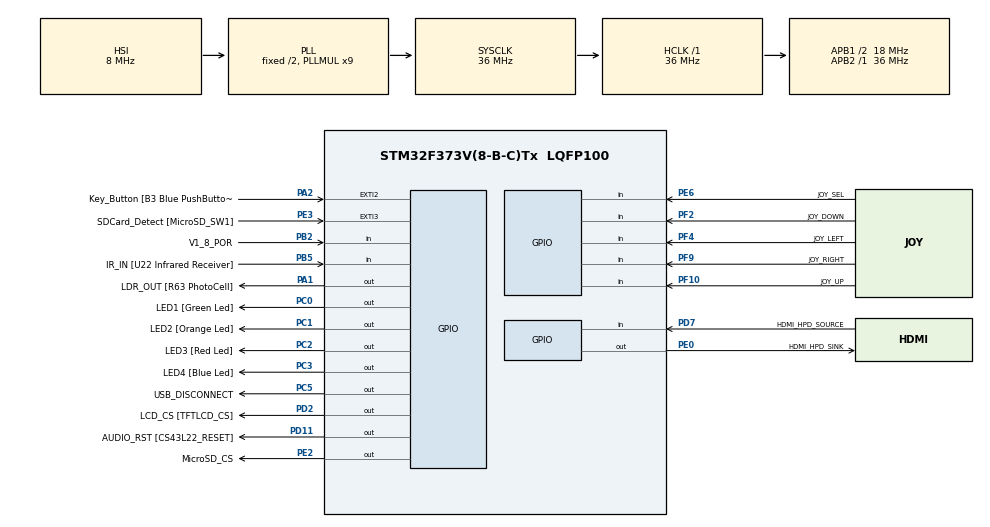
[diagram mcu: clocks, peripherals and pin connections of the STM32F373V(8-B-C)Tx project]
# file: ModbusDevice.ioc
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Mcu.Family=STM32F3
Mcu.Name=STM32F373V(8-B-C)Tx
Mcu.Package=LQFP100
NVIC.PriorityGroup=NVIC_PRIORITYGROUP_0
PA0.GPIO_Label=WAKEUP [B2 PushButton]
PA0.Signal=SYS_WKUP1
PA1.GPIO_Label=LDR_OUT [R63 PhotoCell]
PA1.GPIO_ModeDefaultOutputPP=GPIO_MODE_OUTPUT_PP
PA1.GPIO_PuPd=GPIO_NOPULL
PA1.GPIO_Speed=GPIO_SPEED_FREQ_LOW
PA1.Signal=GPIO_Output
PA10.GPIO_Label=I2C2_SDA [STLM75M2E_SDA]
PA10.GPIO_Mode=GPIO_MODE_AF_OD
PA10.GPIO_PuPd=GPIO_NOPULL
PA10.GPIO_Speed=GPIO_SPEED_FREQ_LOW
PA10.Signal=I2C2_SDA
PA11.Signal=USB_DM
PA12.Signal=USB_DP
PA13.GPIO_Label=TMS/SWDIO
PA13.Signal=SYS_JTMS-SWDIO
PA14.GPIO_Label=TMS/SWCLK
PA14.Signal=SYS_JTCK-SWCLK
PA15.GPIO_Label=TDI
PA15.Signal=SYS_JTDI
PA2.GPIO_Label=Key_Button [B3 Blue PushButton]
PA2.GPIO_ModeDefaultEXTI=GPIO_MODE_EVT_RISING
PA2.GPIO_PuPd=GPIO_NOPULL
PA2.Signal=GPXTI2
PA3.GPIO_Label=COM_IN+
PA3.GPIO_Mode=GPIO_MODE_ANALOG
PA3.GPIO_PuPd=GPIO_NOPULL
PA3.Signal=COMP2_INP
PA4.GPIO_Label=ADC_DAC_SAR1 [CN11]
PA4.GPIO_Mode=GPIO_MODE_ANALOG
PA4.GPIO_PuPd=GPIO_NOPULL
PA4.Signal=ADC1_IN4
PA5.GPIO_Label=ADC_DAC_SAR2 [CN10]
PA5.GPIO_Mode=GPIO_MODE_ANALOG
PA5.GPIO_PuPd=GPIO_NOPULL
PA5.Signal=ADC1_IN5
PA6.GPIO_Label=ECG_DAC [ElectroCardiogram]
PA6.GPIO_Mode=GPIO_MODE_ANALOG
PA6.GPIO_PuPd=GPIO_NOPULL
PA6.Signal=COMP_DAC21_group
PA7.GPIO_Label=COMP_OUT [LD9 Green Led]
PA7.GPIO_Mode=GPIO_MODE_AF_PP
PA7.GPIO_PuPd=GPIO_NOPULL
PA7.GPIO_Speed=GPIO_SPEED_FREQ_LOW
PA7.Signal=COMP2_OUT
PA8.GPIO_Label=I2C2_SMB [STLM75M2E_INT]
PA8.GPIO_Mode=GPIO_MODE_AF_OD
PA8.GPIO_PuPd=GPIO_NOPULL
PA8.GPIO_Speed=GPIO_SPEED_FREQ_LOW
PA8.Signal=I2C2_SMBA
PA9.GPIO_Label=I2C2_SCL [STLM75M2E_SCL]
PA9.GPIO_Mode=GPIO_MODE_AF_OD
PA9.GPIO_PuPd=GPIO_NOPULL
PA9.GPIO_Speed=GPIO_SPEED_FREQ_LOW
PA9.Signal=I2C2_SCL
PB0.GPIO_Label=MIC_IN [Microphone]
PB0.GPIO_Mode=GPIO_MODE_ANALOG
PB0.GPIO_PuPd=GPIO_NOPULL
PB0.Signal=ADC1_IN8
PB1.GPIO_Label=ADC_POT_IN [RV3 Potentiometer]
PB1.GPIO_Mode=GPIO_MODE_ANALOG
PB1.GPIO_PuPd=GPIO_NOPULL
PB1.Signal=ADC1_IN9
PB2.GPIO_Label=V1_8_POR
PB2.GPIO_Mode=GPIO_MODE_INPUT
PB2.GPIO_PuPd=GPIO_NOPULL
PB2.Signal=GPIO_Input
PB3.GPIO_Label=TDO/SWO
PB3.Signal=SYS_JTDO-TRACESWO
PB4.GPIO_Label=TRST
PB4.Signal=SYS_NJTRST
PB5.GPIO_Label=IR_IN [U22 Infrared Receiver]
PB5.GPIO_Mode=GPIO_MODE_INPUT
PB5.GPIO_PuPd=GPIO_NOPULL
PB5.Signal=GPIO_Input
PB6.GPIO_Label=I2C1_SCL [HDMI_SCL]
PB6.GPIO_Mode=GPIO_MODE_AF_OD
PB6.GPIO_PuPd=GPIO_NOPULL
PB6.GPIO_Speed=GPIO_SPEED_FREQ_LOW
PB6.Signal=I2C1_SCL
PB7.GPIO_Label=I2C1_SDA [HDMI_SDA]
PB7.GPIO_Mode=GPIO_MODE_AF_OD
PB7.GPIO_PuPd=GPIO_NOPULL
PB7.GPIO_Speed=GPIO_SPEED_FREQ_LOW
PB7.Signal=I2C1_SDA
PB8.GPIO_Label=HDMI_CEC
PB8.GPIO_Mode=GPIO_MODE_AF_PP
PB8.GPIO_PuPd=GPIO_NOPULL
PB8.GPIO_Speed=GPIO_SPEED_FREQ_LOW
PB8.Signal=CEC
PB9.GPIO_FM9=__NULL
PB9.GPIO_Label=IR_LED [LD10 Infrared Led]
PB9.GPIO_ModeDefaultPP=GPIO_MODE_AF_PP
PB9.GPIO_PuPd=GPIO_NOPULL
PB9.GPIO_Speed=GPIO_SPEED_FREQ_LOW
PB9.Signal=IR_OUT
PC0.GPIO_Label=LED1 [Green Led]
PC0.GPIO_ModeDefaultOutputPP=GPIO_MODE_OUTPUT_OD
PC0.GPIO_PuPd=GPIO_NOPULL
PC0.GPIO_Speed=GPIO_SPEED_FREQ_LOW
PC0.Signal=GPIO_Output
PC1.GPIO_Label=LED2 [Orange Led]
PC1.GPIO_ModeDefaultOutputPP=GPIO_MODE_OUTPUT_OD
PC1.GPIO_PuPd=GPIO_NOPULL
PC1.GPIO_Speed=GPIO_SPEED_FREQ_LOW
PC1.Signal=GPIO_Output
PC10.GPIO_Label=SPI3_SCK [TFTLCD_SCL]
PC10.GPIO_Mode=GPIO_MODE_AF_PP
PC10.GPIO_PuPd=GPIO_NOPULL
PC10.GPIO_Speed=GPIO_SPEED_FREQ_LOW
PC10.Signal=SPI3_SCK
PC11.GPIO_Label=SPI3_MISO [TFTLCD_SDO]
PC11.GPIO_Mode=GPIO_MODE_AF_PP
PC11.GPIO_PuPd=GPIO_NOPULL
PC11.GPIO_Speed=GPIO_SPEED_FREQ_LOW
PC11.Signal=SPI3_MISO
PC12.GPIO_Label=SPI3_MOSI [TFTLCD_SDI]
PC12.GPIO_Mode=GPIO_MODE_AF_PP
PC12.GPIO_PuPd=GPIO_NOPULL
PC12.GPIO_Speed=GPIO_SPEED_FREQ_LOW
PC12.Signal=SPI3_MOSI
PC14-OSC32_IN.GPIO_Label=PC14-OSC32_IN
PC14-OSC32_IN.Signal=RCC_OSC32_IN
PC15-OSC32_OUT.GPIO_Label=PC15-OSC32_OUT
PC15-OSC32_OUT.Signal=RCC_OSC32_OUT
PC2.GPIO_Label=LED3 [Red Led]
PC2.GPIO_ModeDefaultOutputPP=GPIO_MODE_OUTPUT_OD
PC2.GPIO_PuPd=GPIO_NOPULL
PC2.GPIO_Speed=GPIO_SPEED_FREQ_LOW
PC2.Signal=GPIO_Output
PC3.GPIO_Label=LED4 [Blue Led]
PC3.GPIO_ModeDefaultOutputPP=GPIO_MODE_OUTPUT_OD
PC3.GPIO_PuPd=GPIO_NOPULL
PC3.GPIO_Speed=GPIO_SPEED_FREQ_LOW
PC3.Signal=GPIO_Output
PC5.GPIO_Label=USB_DISCONNECT
PC5.GPIO_ModeDefaultOutputPP=GPIO_MODE_OUTPUT_PP
PC5.GPIO_PuPd=GPIO_NOPULL
PC5.GPIO_Speed=GPIO_SPEED_FREQ_LOW
PC5.Signal=GPIO_Output
PC6.GPIO_Label=I2S_CMD [CS43L22_LRCK]
PC6.GPIO_Mode=GPIO_MODE_AF_PP
PC6.GPIO_PuPd=GPIO_NOPULL
PC6.GPIO_Speed=GPIO_SPEED_FREQ_LOW
PC6.Signal=I2S1_WS
PC7.GPIO_Label=I2S_CK [CS43L22_SCLK]
PC7.GPIO_Mode=GPIO_MODE_AF_PP
PC7.GPIO_PuPd=GPIO_NOPULL
PC7.GPIO_Speed=GPIO_SPEED_FREQ_LOW
PC7.Signal=I2S1_CK
PC8.GPIO_Label=I2S_MCLK [CS43L22_MCLK]
PC8.GPIO_Mode=GPIO_MODE_AF_PP
PC8.GPIO_PuPd=GPIO_NOPULL
PC8.GPIO_Speed=GPIO_SPEED_FREQ_LOW
PC8.Signal=I2S1_MCK
PC9.GPIO_Label=I2S_DIN [CS43L22_SDIN]
PC9.GPIO_Mode=GPIO_MODE_AF_PP
PC9.GPIO_PuPd=GPIO_NOPULL
PC9.GPIO_Speed=GPIO_SPEED_FREQ_LOW
PC9.Signal=I2S1_SD
PD0.GPIO_Label=CAN_RX [SN65HVD230D_R]
PD0.GPIO_Mode=GPIO_MODE_AF_PP
PD0.GPIO_PuPd=GPIO_NOPULL
PD0.GPIO_Speed=GPIO_SPEED_FREQ_LOW
PD0.Signal=CAN_RX
PD1.GPIO_Label=CAN_TX [SN65HVD230D_D]
PD1.GPIO_Mode=GPIO_MODE_AF_PP
PD1.GPIO_PuPd=GPIO_NOPULL
PD1.GPIO_Speed=GPIO_SPEED_FREQ_LOW
PD1.Signal=CAN_TX
PD11.GPIO_Label=AUDIO_RST [CS43L22_RESET]
PD11.GPIO_ModeDefaultOutputPP=GPIO_MODE_OUTPUT_PP
PD11.GPIO_PuPd=GPIO_NOPULL
PD11.GPIO_Speed=GPIO_SPEED_FREQ_LOW
PD11.Signal=GPIO_Output
PD12.GPIO_Label=SLIDER_1 [Touch_Slider]
PD12.GPIO_ModeDefaultPP=GPIO_MODE_AF_PP
PD12.GPIO_PuPd=GPIO_NOPULL
PD12.GPIO_Speed=GPIO_SPEED_FREQ_LOW
PD12.Signal=TSC_G8_IO1
PD13.GPIO_Label=SLIDER_2 [Touch_Slider]
PD13.GPIO_ModeDefaultPP=GPIO_MODE_AF_PP
PD13.GPIO_PuPd=GPIO_NOPULL
PD13.GPIO_Speed=GPIO_SPEED_FREQ_LOW
PD13.Signal=TSC_G8_IO2
PD14.GPIO_Label=SLIDER_3 [Touch_Slider]
PD14.GPIO_ModeDefaultPP=GPIO_MODE_AF_PP
PD14.GPIO_PuPd=GPIO_NOPULL
PD14.GPIO_Speed=GPIO_SPEED_FREQ_LOW
PD14.Signal=TSC_G8_IO3
PD15.GPIO_Label=SLIDER_CT [Touch_Slider]
PD15.GPIO_ModeDefaultPP=GPIO_MODE_AF_PP
PD15.GPIO_PuPd=GPIO_NOPULL
PD15.GPIO_Speed=GPIO_SPEED_FREQ_LOW
PD15.Signal=TSC_G8_IO4
PD2.GPIO_Label=LCD_CS [TFTLCD_CS]
PD2.GPIO_ModeDefaultOutputPP=GPIO_MODE_OUTPUT_OD
PD2.GPIO_PuPd=GPIO_NOPULL
PD2.GPIO_Speed=GPIO_SPEED_FREQ_LOW
PD2.Signal=GPIO_Output
PD3.GPIO_Label=USART2_CTS [ST3241_R4OUT]
PD3.GPIO_Mode=GPIO_MODE_AF_PP
PD3.GPIO_PuPd=GPIO_NOPULL
PD3.GPIO_Speed=GPIO_SPEED_FREQ_LOW
PD3.Signal=USART2_CTS
PD4.GPIO_Label=USART2_RTS [ST3241_T1IN]
PD4.GPIO_Mode=GPIO_MODE_AF_PP
PD4.GPIO_PuPd=GPIO_NOPULL
PD4.GPIO_Speed=GPIO_SPEED_FREQ_LOW
PD4.Signal=USART2_RTS
PD5.GPIO_Label=USART2_TX [ST3241_T2IN]
PD5.GPIO_Mode=GPIO_MODE_AF_PP
PD5.GPIO_PuPd=GPIO_NOPULL
PD5.GPIO_Speed=GPIO_SPEED_FREQ_LOW
PD5.Signal=USART2_TX
PD6.GPIO_Label=USART2_RX [ST3241_R3OUT]
PD6.GPIO_Mode=GPIO_MODE_AF_PP
PD6.GPIO_PuPd=GPIO_NOPULL
PD6.GPIO_Speed=GPIO_SPEED_FREQ_LOW
PD6.Signal=USART2_RX
PD7.GPIO_Label=HDMI_HPD_SOURCE
PD7.GPIO_Mode=GPIO_MODE_INPUT
PD7.GPIO_PuPd=GPIO_NOPULL
PD7.Signal=GPIO_Input
PE0.GPIO_Label=HDMI_HPD_SINK
PE0.GPIO_ModeDefaultOutputPP=GPIO_MODE_OUTPUT_OD
PE0.GPIO_PuPd=GPIO_NOPULL
PE0.GPIO_Speed=GPIO_SPEED_FREQ_LOW
PE0.Signal=GPIO_Output
PE11.GPIO_Label=ADC_SD [CN9]
PE11.GPIO_Mode=GPIO_MODE_ANALOG
PE11.GPIO_PuPd=GPIO_NOPULL
PE11.Signal=SDADC1_AIN1P
PE12.GPIO_Label=ECG [ElectroCardiogram]
PE12.GPIO_Mode=GPIO_MODE_ANALOG
PE12.GPIO_PuPd=GPIO_NOPULL
PE12.Signal=SDADC1_AIN0P
PE14.GPIO_Label=PRESSURE_TEMP [MPX2102_GND]
PE14.GPIO_Mode=GPIO_MODE_ANALOG
PE14.GPIO_PuPd=GPIO_NOPULL
PE14.Signal=SDADC2_AIN1P
PE2.GPIO_Label=MicroSD_CS
PE2.GPIO_ModeDefaultOutputPP=GPIO_MODE_OUTPUT_OD
PE2.GPIO_PuPd=GPIO_NOPULL
PE2.GPIO_Speed=GPIO_SPEED_FREQ_LOW
PE2.Signal=GPIO_Output
PE3.GPIO_Label=SDCard_Detect [MicroSD_SW1]
PE3.GPIO_ModeDefaultEXTI=GPIO_MODE_EVT_RISING
PE3.GPIO_PuPd=GPIO_PULLUP
PE3.Signal=GPXTI3
PE4.GPIO_Label=SHIELD [Touch_Slider]
PE4.GPIO_ModeDefaultPP=GPIO_MODE_AF_PP
PE4.GPIO_PuPd=GPIO_NOPULL
PE4.GPIO_Speed=GPIO_SPEED_FREQ_LOW
PE4.Signal=TSC_G7_IO3
PE5.GPIO_Label=SHIELD_CT [Touch_Slider]
PE5.GPIO_ModeDefaultPP=GPIO_MODE_AF_PP
PE5.GPIO_PuPd=GPIO_NOPULL
PE5.GPIO_Speed=GPIO_SPEED_FREQ_LOW
PE5.Signal=TSC_G7_IO4
PE6.GPIO_Label=JOY_SEL
PE6.GPIO_Mode=GPIO_MODE_INPUT
PE6.GPIO_PuPd=GPIO_PULLDOWN
PE6.Signal=GPIO_Input
PE7.GPIO_Label=RTD_IN [Temperature_Sensor]
PE7.GPIO_Mode=GPIO_MODE_ANALOG
PE7.GPIO_PuPd=GPIO_NOPULL
PE7.Signal=SDADC1_AIN3P
PE8.GPIO_Label=PRESSURE_P [MPX2102_Vout+]
PE8.GPIO_Mode=GPIO_MODE_ANALOG
PE8.GPIO_PuPd=GPIO_NOPULL
PE8.Signal=SDADC1_AIN8P
PE9.GPIO_Label=PRESSURE_N [MPX2102_Vout-]
PE9.GPIO_Mode=GPIO_MODE_ANALOG
PE9.GPIO_PuPd=GPIO_NOPULL
PE9.Signal=SDADC1_AIN8M
PF0-OSC_IN.GPIO_Label=PF0-OSC_IN
PF0-OSC_IN.Signal=RCC_OSC_IN
PF1-OSC_OUT.GPIO_Label=PF1-OSC_OUT
PF1-OSC_OUT.Signal=RCC_OSC_OUT
PF10.GPIO_Label=JOY_UP
PF10.GPIO_Mode=GPIO_MODE_INPUT
PF10.GPIO_PuPd=GPIO_PULLDOWN
PF10.Signal=GPIO_Input
PF2.GPIO_Label=JOY_DOWN
PF2.GPIO_Mode=GPIO_MODE_INPUT
PF2.GPIO_PuPd=GPIO_PULLDOWN
PF2.Signal=GPIO_Input
PF4.GPIO_Label=JOY_LEFT
PF4.GPIO_Mode=GPIO_MODE_INPUT
PF4.GPIO_PuPd=GPIO_PULLDOWN
PF4.Signal=GPIO_Input
PF9.GPIO_Label=JOY_RIGHT
PF9.GPIO_Mode=GPIO_MODE_INPUT
PF9.GPIO_PuPd=GPIO_PULLDOWN
PF9.Signal=GPIO_Input
ProjectManager.HeapSize=0x200
ProjectManager.StackSize=0x400
ProjectManager.TargetToolchain=STM32CubeIDE
RCC.AHBFreq_Value=36000000
RCC.APB1CLKDivider=RCC_HCLK_DIV2
RCC.APB1Freq_Value=18000000
RCC.APB1TimFreq_Value=36000000
RCC.APB2Freq_Value=36000000
RCC.APB2TimFreq_Value=36000000
RCC.CortexFreq_Value=36000000
RCC.HCLKFreq_Value=36000000
RCC.HSE_VALUE=8000000
RCC.HSI_VALUE=8000000
RCC.LSE_VALUE=32768
RCC.PLLMUL=RCC_PLL_MUL9
RCC.PRESCALERUSB=RCC_USBCLKSOURCE_PLL_DIV1_5
RCC.SDADCPresc=RCC_SDADCSYSCLK_DIV12
RCC.SYSCLKFreq_VALUE=36000000
RCC.SYSCLKSource=RCC_SYSCLKSOURCE_PLLCLK
RCC.USBFreq_Value=24000000
SH.COMP_DAC21_group.0=DAC2_OUT1
board=STM32373C-EVAL

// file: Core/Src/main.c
/* USER CODE BEGIN Header */
/**
  ******************************************************************************
  * @file           : main.c
  * @brief          : Main program body
  ******************************************************************************
  * @attention
  *
  * Copyright (c) 2023 STMicroelectronics.
  * All rights reserved.
  *
  * This software is licensed under terms that can be found in the LICENSE file
  * in the root directory of this software component.
  * If no LICENSE file comes with this software, it is provided AS-IS.
  *
  ******************************************************************************
  */
/* USER CODE END Header */
#include "main.h"

/* USER CODE BEGIN Includes */
#include "ModbusDevice.h"
/* USER CODE END Includes */

void SystemClock_Config(void);
static void MX_GPIO_Init(void);

int main(void)
{

  /* MCU Configuration--------------------------------------------------------*/

  /* Reset of all peripherals, Initializes the Flash interface and the Systick. */
  HAL_Init();

  /* Configure the system clock */
  SystemClock_Config();

  /* Initialize all configured peripherals */
  MX_GPIO_Init();
  /* USER CODE BEGIN 2 */
  ModbusDevice_Main();
  /* USER CODE END 2 */

  /* Infinite loop */
  while (1)
  {

  }
}

void SystemClock_Config(void)
{
  RCC_OscInitTypeDef RCC_OscInitStruct = {0};
  RCC_ClkInitTypeDef RCC_ClkInitStruct = {0};

  /** Initializes the RCC Oscillators according to the specified parameters
  * in the RCC_OscInitTypeDef structure.
  */
  RCC_OscInitStruct.OscillatorType = RCC_OSCILLATORTYPE_HSI;
  RCC_OscInitStruct.HSIState = RCC_HSI_ON;
  RCC_OscInitStruct.HSICalibrationValue = RCC_HSICALIBRATION_DEFAULT;
  RCC_OscInitStruct.PLL.PLLState = RCC_PLL_ON;
  RCC_OscInitStruct.PLL.PLLSource = RCC_PLLSOURCE_HSI;
  RCC_OscInitStruct.PLL.PLLMUL = RCC_PLL_MUL9;
  if (HAL_RCC_OscConfig(&RCC_OscInitStruct) != HAL_OK)
  {
    Error_Handler();
  }

  /** Initializes the CPU, AHB and APB buses clocks
  */
  RCC_ClkInitStruct.ClockType = RCC_CLOCKTYPE_HCLK|RCC_CLOCKTYPE_SYSCLK
                              |RCC_CLOCKTYPE_PCLK1|RCC_CLOCKTYPE_PCLK2;
  RCC_ClkInitStruct.SYSCLKSource = RCC_SYSCLKSOURCE_PLLCLK;
  RCC_ClkInitStruct.AHBCLKDivider = RCC_SYSCLK_DIV1;
  RCC_ClkInitStruct.APB1CLKDivider = RCC_HCLK_DIV2;
  RCC_ClkInitStruct.APB2CLKDivider = RCC_HCLK_DIV1;

  if (HAL_RCC_ClockConfig(&RCC_ClkInitStruct, FLASH_LATENCY_1) != HAL_OK)
  {
    Error_Handler();
  }
}

static void MX_GPIO_Init(void)
{
  GPIO_InitTypeDef GPIO_InitStruct = {0};

  /* GPIO Ports Clock Enable */
  __HAL_RCC_GPIOE_CLK_ENABLE();
  __HAL_RCC_GPIOC_CLK_ENABLE();
  __HAL_RCC_GPIOF_CLK_ENABLE();
  __HAL_RCC_GPIOA_CLK_ENABLE();
  __HAL_RCC_GPIOB_CLK_ENABLE();
  __HAL_RCC_GPIOD_CLK_ENABLE();

  /*Configure GPIO pin Output Level */
  HAL_GPIO_WritePin(GPIOE, MicroSD_CS_Pin|HDMI_HPD_SINK_Pin, GPIO_PIN_RESET);

  /*Configure GPIO pin Output Level */
  HAL_GPIO_WritePin(GPIOC, LED1_Pin|LED2_Pin|LED3_Pin|LED4_Pin
                          |USB_DISCONNECT_Pin, GPIO_PIN_RESET);

  /*Configure GPIO pin Output Level */
  HAL_GPIO_WritePin(LDR_OUT_GPIO_Port, LDR_OUT_Pin, GPIO_PIN_RESET);

  /*Configure GPIO pin Output Level */
  HAL_GPIO_WritePin(GPIOD, AUDIO_RST_Pin|LCD_CS_Pin, GPIO_PIN_RESET);

  /*Configure GPIO pins : MicroSD_CS_Pin HDMI_HPD_SINK_Pin */
  GPIO_InitStruct.Pin = MicroSD_CS_Pin|HDMI_HPD_SINK_Pin;
  GPIO_InitStruct.Mode = GPIO_MODE_OUTPUT_OD;
  GPIO_InitStruct.Pull = GPIO_NOPULL;
  GPIO_InitStruct.Speed = GPIO_SPEED_FREQ_LOW;
  HAL_GPIO_Init(GPIOE, &GPIO_InitStruct);

  /*Configure GPIO pin : SDCard_Detect_Pin */
  GPIO_InitStruct.Pin = SDCard_Detect_Pin;
  GPIO_InitStruct.Mode = GPIO_MODE_EVT_RISING;
  GPIO_InitStruct.Pull = GPIO_PULLUP;
  HAL_GPIO_Init(SDCard_Detect_GPIO_Port, &GPIO_InitStruct);

  /*Configure GPIO pins : SHIELD_Pin SHIELD_CT_Pin */
  GPIO_InitStruct.Pin = SHIELD_Pin|SHIELD_CT_Pin;
  GPIO_InitStruct.Mode = GPIO_MODE_AF_PP;
  GPIO_InitStruct.Pull = GPIO_NOPULL;
  GPIO_InitStruct.Speed = GPIO_SPEED_FREQ_LOW;
  GPIO_InitStruct.Alternate = GPIO_AF3_TSC;
  HAL_GPIO_Init(GPIOE, &GPIO_InitStruct);

  /*Configure GPIO pin : JOY_SEL_Pin */
  GPIO_InitStruct.Pin = JOY_SEL_Pin;
  GPIO_InitStruct.Mode = GPIO_MODE_INPUT;
  GPIO_InitStruct.Pull = GPIO_PULLDOWN;
  HAL_GPIO_Init(JOY_SEL_GPIO_Port, &GPIO_InitStruct);

  /*Configure GPIO pins : JOY_RIGHT_Pin JOY_UP_Pin JOY_DOWN_Pin JOY_LEFT_Pin */
  GPIO_InitStruct.Pin = JOY_RIGHT_Pin|JOY_UP_Pin|JOY_DOWN_Pin|JOY_LEFT_Pin;
  GPIO_InitStruct.Mode = GPIO_MODE_INPUT;
  GPIO_InitStruct.Pull = GPIO_PULLDOWN;
  HAL_GPIO_Init(GPIOF, &GPIO_InitStruct);

  /*Configure GPIO pins : LED1_Pin LED2_Pin LED3_Pin LED4_Pin */
  GPIO_InitStruct.Pin = LED1_Pin|LED2_Pin|LED3_Pin|LED4_Pin;
  GPIO_InitStruct.Mode = GPIO_MODE_OUTPUT_OD;
  GPIO_InitStruct.Pull = GPIO_NOPULL;
  GPIO_InitStruct.Speed = GPIO_SPEED_FREQ_LOW;
  HAL_GPIO_Init(GPIOC, &GPIO_InitStruct);

  /*Configure GPIO pin : LDR_OUT_Pin */
  GPIO_InitStruct.Pin = LDR_OUT_Pin;
  GPIO_InitStruct.Mode = GPIO_MODE_OUTPUT_PP;
  GPIO_InitStruct.Pull = GPIO_NOPULL;
  GPIO_InitStruct.Speed = GPIO_SPEED_FREQ_LOW;
  HAL_GPIO_Init(LDR_OUT_GPIO_Port, &GPIO_InitStruct);

  /*Configure GPIO pin : Key_Button_Pin */
  GPIO_InitStruct.Pin = Key_Button_Pin;
  GPIO_InitStruct.Mode = GPIO_MODE_EVT_RISING;
  GPIO_InitStruct.Pull = GPIO_NOPULL;
  HAL_GPIO_Init(Key_Button_GPIO_Port, &GPIO_InitStruct);

  /*Configure GPIO pins : COM_IN__Pin ADC_DAC_SAR1_Pin ADC_DAC_SAR2_Pin ECG_DAC_Pin */
  GPIO_InitStruct.Pin = COM_IN__Pin|ADC_DAC_SAR1_Pin|ADC_DAC_SAR2_Pin|ECG_DAC_Pin;
  GPIO_InitStruct.Mode = GPIO_MODE_ANALOG;
  GPIO_InitStruct.Pull = GPIO_NOPULL;
  HAL_GPIO_Init(GPIOA, &GPIO_InitStruct);

  /*Configure GPIO pin : COMP_OUT_Pin */
  GPIO_InitStruct.Pin = COMP_OUT_Pin;
  GPIO_InitStruct.Mode = GPIO_MODE_AF_PP;
  GPIO_InitStruct.Pull = GPIO_NOPULL;
  GPIO_InitStruct.Speed = GPIO_SPEED_FREQ_LOW;
  GPIO_InitStruct.Alternate = GPIO_AF8_COMP2;
  HAL_GPIO_Init(COMP_OUT_GPIO_Port, &GPIO_InitStruct);

  /*Configure GPIO pin : USB_DISCONNECT_Pin */
  GPIO_InitStruct.Pin = USB_DISCONNECT_Pin;
  GPIO_InitStruct.Mode = GPIO_MODE_OUTPUT_PP;
  GPIO_InitStruct.Pull = GPIO_NOPULL;
  GPIO_InitStruct.Speed = GPIO_SPEED_FREQ_LOW;
  HAL_GPIO_Init(USB_DISCONNECT_GPIO_Port, &GPIO_InitStruct);

  /*Configure GPIO pins : MIC_IN_Pin ADC_POT_IN_Pin */
  GPIO_InitStruct.Pin = MIC_IN_Pin|ADC_POT_IN_Pin;
  GPIO_InitStruct.Mode = GPIO_MODE_ANALOG;
  GPIO_InitStruct.Pull = GPIO_NOPULL;
  HAL_GPIO_Init(GPIOB, &GPIO_InitStruct);

  /*Configure GPIO pins : V1_8_POR_Pin IR_IN_Pin */
  GPIO_InitStruct.Pin = V1_8_POR_Pin|IR_IN_Pin;
  GPIO_InitStruct.Mode = GPIO_MODE_INPUT;
  GPIO_InitStruct.Pull = GPIO_NOPULL;
  HAL_GPIO_Init(GPIOB, &GPIO_InitStruct);

  /*Configure GPIO pins : RTD_IN_Pin PRESSURE_P_Pin PRESSURE_N_Pin ADC_SD_Pin
                           ECG_Pin PRESSURE_TEMP_Pin */
  GPIO_InitStruct.Pin = RTD_IN_Pin|PRESSURE_P_Pin|PRESSURE_N_Pin|ADC_SD_Pin
                          |ECG_Pin|PRESSURE_TEMP_Pin;
  GPIO_InitStruct.Mode = GPIO_MODE_ANALOG;
  GPIO_InitStruct.Pull = GPIO_NOPULL;
  HAL_GPIO_Init(GPIOE, &GPIO_InitStruct);

  /*Configure GPIO pin : AUDIO_RST_Pin */
  GPIO_InitStruct.Pin = AUDIO_RST_Pin;
  GPIO_InitStruct.Mode = GPIO_MODE_OUTPUT_PP;
  GPIO_InitStruct.Pull = GPIO_NOPULL;
  GPIO_InitStruct.Speed = GPIO_SPEED_FREQ_LOW;
  HAL_GPIO_Init(AUDIO_RST_GPIO_Port, &GPIO_InitStruct);

  /*Configure GPIO pins : SLIDER_1_Pin SLIDER_2_Pin SLIDER_3_Pin SLIDER_CT_Pin */
  GPIO_InitStruct.Pin = SLIDER_1_Pin|SLIDER_2_Pin|SLIDER_3_Pin|SLIDER_CT_Pin;
  GPIO_InitStruct.Mode = GPIO_MODE_AF_PP;
  GPIO_InitStruct.Pull = GPIO_NOPULL;
  GPIO_InitStruct.Speed = GPIO_SPEED_FREQ_LOW;
  GPIO_InitStruct.Alternate = GPIO_AF3_TSC;
  HAL_GPIO_Init(GPIOD, &GPIO_InitStruct);

  /*Configure GPIO pins : I2S_CMD_Pin I2S_CK_Pin I2S_MCLK_Pin I2S_DIN_Pin */
  GPIO_InitStruct.Pin = I2S_CMD_Pin|I2S_CK_Pin|I2S_MCLK_Pin|I2S_DIN_Pin;
  GPIO_InitStruct.Mode = GPIO_MODE_AF_PP;
  GPIO_InitStruct.Pull = GPIO_NOPULL;
  GPIO_InitStruct.Speed = GPIO_SPEED_FREQ_LOW;
  GPIO_InitStruct.Alternate = GPIO_AF5_SPI1;
  HAL_GPIO_Init(GPIOC, &GPIO_InitStruct);

  /*Configure GPIO pins : I2C2_SMB_Pin I2C2_SCL_Pin I2C2_SDA_Pin */
  GPIO_InitStruct.Pin = I2C2_SMB_Pin|I2C2_SCL_Pin|I2C2_SDA_Pin;
  GPIO_InitStruct.Mode = GPIO_MODE_AF_OD;
  GPIO_InitStruct.Pull = GPIO_NOPULL;
  GPIO_InitStruct.Speed = GPIO_SPEED_FREQ_LOW;
  GPIO_InitStruct.Alternate = GPIO_AF4_I2C2;
  HAL_GPIO_Init(GPIOA, &GPIO_InitStruct);

  /*Configure GPIO pins : PA11 PA12 */
  GPIO_InitStruct.Pin = GPIO_PIN_11|GPIO_PIN_12;
  GPIO_InitStruct.Mode = GPIO_MODE_AF_PP;
  GPIO_InitStruct.Pull = GPIO_NOPULL;
  GPIO_InitStruct.Speed = GPIO_SPEED_FREQ_HIGH;
  GPIO_InitStruct.Alternate = GPIO_AF14_USB;
  HAL_GPIO_Init(GPIOA, &GPIO_InitStruct);

  /*Configure GPIO pins : SPI3_SCK_Pin SPI3_MISO_Pin SPI3_MOSI_Pin */
  GPIO_InitStruct.Pin = SPI3_SCK_Pin|SPI3_MISO_Pin|SPI3_MOSI_Pin;
  GPIO_InitStruct.Mode = GPIO_MODE_AF_PP;
  GPIO_InitStruct.Pull = GPIO_NOPULL;
  GPIO_InitStruct.Speed = GPIO_SPEED_FREQ_LOW;
  GPIO_InitStruct.Alternate = GPIO_AF6_SPI3;
  HAL_GPIO_Init(GPIOC, &GPIO_InitStruct);

  /*Configure GPIO pins : CAN_RX_Pin CAN_TX_Pin */
  GPIO_InitStruct.Pin = CAN_RX_Pin|CAN_TX_Pin;
  GPIO_InitStruct.Mode = GPIO_MODE_AF_PP;
  GPIO_InitStruct.Pull = GPIO_NOPULL;
  GPIO_InitStruct.Speed = GPIO_SPEED_FREQ_LOW;
  GPIO_InitStruct.Alternate = GPIO_AF7_CAN;
  HAL_GPIO_Init(GPIOD, &GPIO_InitStruct);

  /*Configure GPIO pin : LCD_CS_Pin */
  GPIO_InitStruct.Pin = LCD_CS_Pin;
  GPIO_InitStruct.Mode = GPIO_MODE_OUTPUT_OD;
  GPIO_InitStruct.Pull = GPIO_NOPULL;
  GPIO_InitStruct.Speed = GPIO_SPEED_FREQ_LOW;
  HAL_GPIO_Init(LCD_CS_GPIO_Port, &GPIO_InitStruct);

  /*Configure GPIO pins : USART2_CTS_Pin USART2_RTS_Pin USART2_TX_Pin USART2_RX_Pin */
  GPIO_InitStruct.Pin = USART2_CTS_Pin|USART2_RTS_Pin|USART2_TX_Pin|USART2_RX_Pin;
  GPIO_InitStruct.Mode = GPIO_MODE_AF_PP;
  GPIO_InitStruct.Pull = GPIO_NOPULL;
  GPIO_InitStruct.Speed = GPIO_SPEED_FREQ_LOW;
  GPIO_InitStruct.Alternate = GPIO_AF7_USART2;
  HAL_GPIO_Init(GPIOD, &GPIO_InitStruct);

  /*Configure GPIO pin : HDMI_HPD_SOURCE_Pin */
  GPIO_InitStruct.Pin = HDMI_HPD_SOURCE_Pin;
  GPIO_InitStruct.Mode = GPIO_MODE_INPUT;
  GPIO_InitStruct.Pull = GPIO_NOPULL;
  HAL_GPIO_Init(HDMI_HPD_SOURCE_GPIO_Port, &GPIO_InitStruct);

  /*Configure GPIO pins : I2C1_SCL_Pin I2C1_SDA_Pin */
  GPIO_InitStruct.Pin = I2C1_SCL_Pin|I2C1_SDA_Pin;
  GPIO_InitStruct.Mode = GPIO_MODE_AF_OD;
  GPIO_InitStruct.Pull = GPIO_NOPULL;
  GPIO_InitStruct.Speed = GPIO_SPEED_FREQ_LOW;
  GPIO_InitStruct.Alternate = GPIO_AF4_I2C1;
  HAL_GPIO_Init(GPIOB, &GPIO_InitStruct);

  /*Configure GPIO pin : HDMI_CEC_Pin */
  GPIO_InitStruct.Pin = HDMI_CEC_Pin;
  GPIO_InitStruct.Mode = GPIO_MODE_AF_PP;
  GPIO_InitStruct.Pull = GPIO_NOPULL;
  GPIO_InitStruct.Speed = GPIO_SPEED_FREQ_LOW;
  GPIO_InitStruct.Alternate = GPIO_AF6_CEC;
  HAL_GPIO_Init(HDMI_CEC_GPIO_Port, &GPIO_InitStruct);

  /*Configure GPIO pin : IR_LED_Pin */
  GPIO_InitStruct.Pin = IR_LED_Pin;
  GPIO_InitStruct.Mode = GPIO_MODE_AF_PP;
  GPIO_InitStruct.Pull = GPIO_NOPULL;
  GPIO_InitStruct.Speed = GPIO_SPEED_FREQ_LOW;
  GPIO_InitStruct.Alternate = GPIO_AF6_IR;
  HAL_GPIO_Init(IR_LED_GPIO_Port, &GPIO_InitStruct);

}

void Error_Handler(void)
{
  __disable_irq();
  while (1)
  {
  }
}
